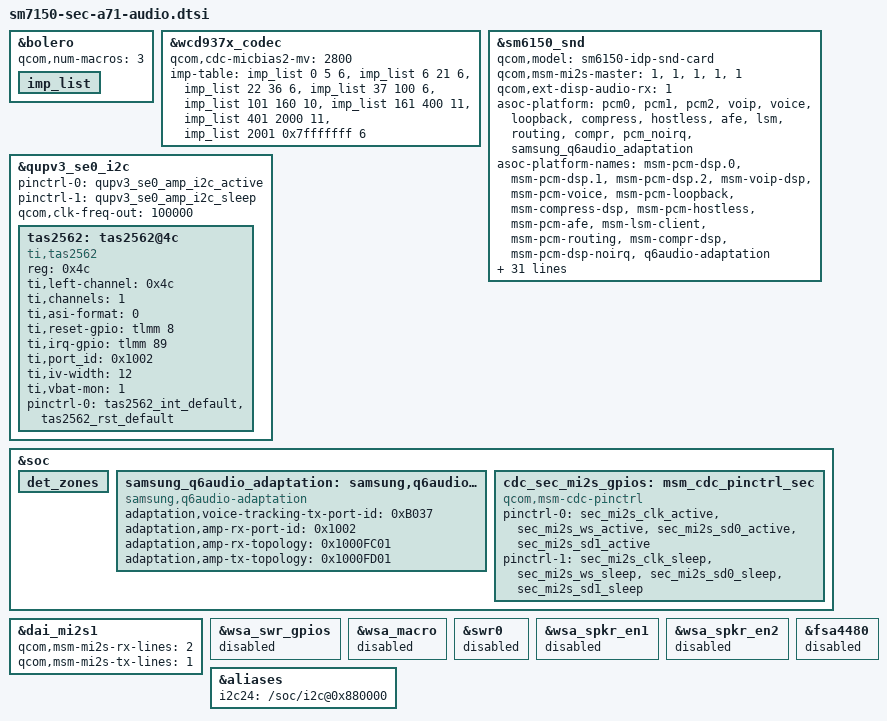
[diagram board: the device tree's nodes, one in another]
/* Copyright (c) 2018, The Linux Foundation. All rights reserved.
 *
 * This program is free software; you can redistribute it and/or modify
 * it under the terms of the GNU General Public License version 2 and
 * only version 2 as published by the Free Software Foundation.
 *
 * This program is distributed in the hope that it will be useful,
 * but WITHOUT ANY WARRANTY; without even the implied warranty of
 * MERCHANTABILITY or FITNESS FOR A PARTICULAR PURPOSE.  See the
 * GNU General Public License for more details.
 */

&bolero {
	qcom,num-macros = <3>;
	imp_list: imp_list {
	#list-imp-cells = <3>;
	};
};

&wcd937x_codec {
	qcom,cdc-micbias2-mv = <2800>;
	imp-table = <&imp_list 0 5 6>,
			 <&imp_list 6 21 6>,
			 <&imp_list 22 36 6>,
			 <&imp_list 37 100 6>,
			 <&imp_list 101 160 10>,
			 <&imp_list 161 400 11>,
			 <&imp_list 401 2000 11>,
			 <&imp_list 2001 0x7fffffff 6>; 
};

&sm6150_snd {
	qcom,model = "sm6150-idp-snd-card";
	qcom,msm-mi2s-master = <1>, <1>, <1>, <1>, <1>;
	qcom,ext-disp-audio-rx = <1>;

	asoc-platform = <&pcm0>, <&pcm1>, <&pcm2>, <&voip>, <&voice>,
			<&loopback>, <&compress>, <&hostless>,
			<&afe>, <&lsm>, <&routing>, <&compr>,
			<&pcm_noirq>, <&samsung_q6audio_adaptation>;
	asoc-platform-names = "msm-pcm-dsp.0", "msm-pcm-dsp.1",
			"msm-pcm-dsp.2", "msm-voip-dsp",
			"msm-pcm-voice", "msm-pcm-loopback",
			"msm-compress-dsp", "msm-pcm-hostless",
			"msm-pcm-afe", "msm-lsm-client",
			"msm-pcm-routing", "msm-compr-dsp",
			"msm-pcm-dsp-noirq", "q6audio-adaptation";
	qcom,audio-routing =
		"AMIC1", "MIC BIAS1",
		"MIC BIAS1", "Analog Mic1",
		"AMIC2", "MIC BIAS2",
		"MIC BIAS2", "Analog Mic2",
		"AMIC3", "MIC BIAS3",
		"MIC BIAS3", "Analog Mic3",
		"IN1_HPHL", "HPHL_OUT",
		"IN2_HPHR", "HPHR_OUT",
		"IN3_AUX", "AUX_OUT",
		"TX SWR_ADC0", "ADC1_OUTPUT",
		"TX SWR_ADC2", "ADC2_OUTPUT",
		"RX_TX DEC0_INP", "TX DEC0 MUX",
		"RX_TX DEC1_INP", "TX DEC1 MUX",
		"RX_TX DEC2_INP", "TX DEC2 MUX",
		"RX_TX DEC3_INP", "TX DEC3 MUX";
	qcom,msm-mbhc-hs-mic-max-threshold-mv = <9999>;
	qcom,msm-mbhc-hs-mic-min-threshold-mv = <640>;
	qcom,msm-mbhc-hphl-swh = <1>;
	qcom,msm-mbhc-gnd-swh = <0>;
	qcom,cdc-dmic01-gpios = <0>;
	qcom,cdc-dmic23-gpios = <0>;
	qcom,fm-lna-gpios = <&tlmm 21 0>;
	asoc-codec  = <&stub_codec>, <&bolero>, <&ext_disp_audio_codec>;
	asoc-codec-names = "msm-stub-codec.1", "bolero_codec",
			   "msm-ext-disp-audio-codec-rx";
	qcom,wsa-max-devs = <0>;

	qcom,codec-max-aux-devs = <1>;
	qcom,codec-aux-devs = <&wcd937x_codec>;
	qcom,msm_audio_ssr_devs = <&audio_apr>, <&q6core>,
				<&lpi_tlmm>, <&bolero>;
	mbhc-button-thres = <&det_zones 13 63>,
			 <&det_zones 88 138>,
			 <&det_zones 125 125>,
			 <&det_zones 225 225>,
			 <&det_zones 475 475>,
			 <&det_zones 620 620>,
			 <&det_zones 620 620>,
			 <&det_zones 620 620>;
	qcom,sec-mi2s-gpios = <&cdc_sec_mi2s_gpios>;
};

&qupv3_se0_i2c {
	pinctrl-names = "default", "sleep";
	pinctrl-0 = <&qupv3_se0_amp_i2c_active>;
	pinctrl-1 = <&qupv3_se0_amp_i2c_sleep>;
	qcom,clk-freq-out = <100000>;
	status = "ok";

	tas2562:tas2562@4c {
		#sound-dai-cells = <0>;
		compatible = "ti,tas2562";
		reg = <0x4c>;
		ti,left-channel = <0x4c>;
		ti,channels = <1>;
		ti,asi-format = <0>;
		ti,reset-gpio = <&tlmm 8 0>;
		ti,irq-gpio = <&tlmm 89 0>;
		ti,port_id = <0x1002>;
		ti,iv-width = <12>;
		ti,vbat-mon = <1>;
		status = "ok";

		pinctrl-names = "default";
		pinctrl-0 = <&tas2562_int_default &tas2562_rst_default>;
	};
};

&soc {
	det_zones: det_zones {
		#list-det-cells = <2>;
	};

	samsung_q6audio_adaptation: samsung,q6audio-adaptation {
		compatible = "samsung,q6audio-adaptation";
		adaptation,voice-tracking-tx-port-id = <0xB037>;
		adaptation,amp-rx-port-id = <0x1002>;
		adaptation,amp-rx-topology = <0x1000FC01>;
		adaptation,amp-tx-topology = <0x1000FD01>;
	};

	cdc_sec_mi2s_gpios: msm_cdc_pinctrl_sec {
		compatible = "qcom,msm-cdc-pinctrl";
		pinctrl-names = "aud_active", "aud_sleep";
		pinctrl-0 = <&sec_mi2s_clk_active &sec_mi2s_ws_active
				 &sec_mi2s_sd0_active &sec_mi2s_sd1_active>;
		pinctrl-1 = <&sec_mi2s_clk_sleep &sec_mi2s_ws_sleep
				 &sec_mi2s_sd0_sleep &sec_mi2s_sd1_sleep>;
	};
};

&dai_mi2s1  {
        qcom,msm-mi2s-rx-lines = <2>;
        qcom,msm-mi2s-tx-lines = <1>;
};

&wsa_swr_gpios {
	status = "disabled";
};

&wsa_macro {
	status = "disabled";
};

&swr0 {
	status = "disabled";
};

&wsa_spkr_en1 {
	status = "disabled";
};
&wsa_spkr_en2 {
	status = "disabled";
};
&fsa4480 {
	status = "disabled";
};

&aliases {
     i2c24 = "/soc/i2c@0x880000";
};
